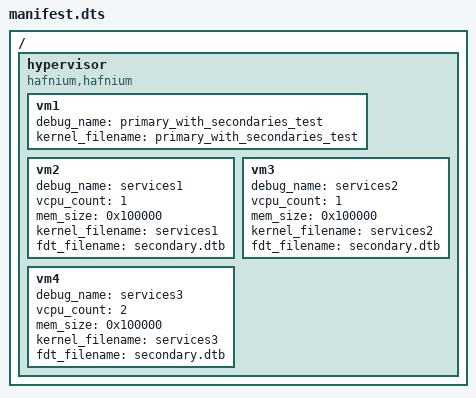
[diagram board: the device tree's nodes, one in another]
/* SPDX-FileCopyrightText: 2019 The Hafnium Authors.     */
/* SPDX-FileCopyrightText: 2023 SANCTUARY Systems GmbH.  */
/* SPDX-License-Identifier: BSD-3-Clause OR GPL-2.0-only */

/dts-v1/;

/ {
	hypervisor {
		compatible = "hafnium,hafnium";
		vm1 {
			debug_name = "primary_with_secondaries_test";
			kernel_filename = "primary_with_secondaries_test";
		};

		vm2 {
			debug_name = "services1";
			vcpu_count = <1>;
			mem_size = <0x100000>;
			kernel_filename = "services1";
			fdt_filename = "secondary.dtb";
		};

		vm3 {
			debug_name = "services2";
			vcpu_count = <1>;
			mem_size = <0x100000>;
			kernel_filename = "services2";
			fdt_filename = "secondary.dtb";
		};

		vm4 {
			debug_name = "services3";
			vcpu_count = <2>;
			mem_size = <0x100000>;
			kernel_filename = "services3";
			fdt_filename = "secondary.dtb";
		};
	};
};
